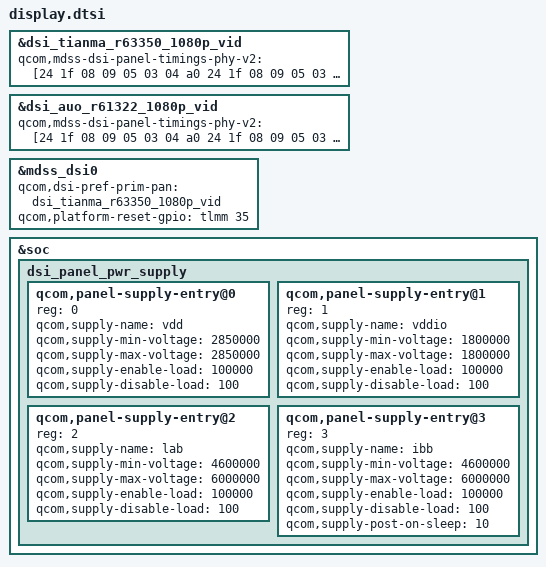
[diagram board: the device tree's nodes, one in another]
/* msm8953-mdss-panels.dtsi */
#include "panel/dsi-panel-tianma-r63350-1080p-video.dtsi"
#include "panel/dsi-panel-auo-r61322-1080p-video.dtsi"

&dsi_tianma_r63350_1080p_vid {
	qcom,mdss-dsi-panel-timings-phy-v2 = [24 1f 08 09 05 03 04 a0
		24 1f 08 09 05 03 04 a0
		24 1f 08 09 05 03 04 a0
		24 1f 08 09 05 03 04 a0
		24 1b 08 09 05 03 04 a0];
};

&dsi_auo_r61322_1080p_vid {
	qcom,mdss-dsi-panel-timings-phy-v2 = [24 1f 08 09 05 03 04 a0
		24 1f 08 09 05 03 04 a0
		24 1f 08 09 05 03 04 a0
		24 1f 08 09 05 03 04 a0
		24 1b 08 09 05 03 04 a0];
};

/* msm8953-mdss.dtsi */
&mdss_dsi0 {
	/delete-property/ vdd-supply;
};

/* msm8953-mtp.dtsi */
&mdss_dsi0 {
	qcom,dsi-pref-prim-pan = <&dsi_tianma_r63350_1080p_vid>;
	qcom,platform-reset-gpio = <&tlmm 35 0>;
};

/* msm8953-oxygen.dtsi */
&mdss_dsi0 {
	/delete-property/ qcom,platform-bklight-en-gpio;
};

&soc {
	dsi_panel_pwr_supply: dsi_panel_pwr_supply {
		#address-cells = <1>;
		#size-cells = <0>;

		qcom,panel-supply-entry@0 {
			reg = <0>;
			qcom,supply-name = "vdd";
			qcom,supply-min-voltage = <2850000>;
			qcom,supply-max-voltage = <2850000>;
			qcom,supply-enable-load = <100000>;
			qcom,supply-disable-load = <100>;
		};

		qcom,panel-supply-entry@1 {
			reg = <1>;
			qcom,supply-name = "vddio";
			qcom,supply-min-voltage = <1800000>;
			qcom,supply-max-voltage = <1800000>;
			qcom,supply-enable-load = <100000>;
			qcom,supply-disable-load = <100>;
		};
		qcom,panel-supply-entry@2 {
			reg = <2>;
			qcom,supply-name = "lab";
			qcom,supply-min-voltage = <4600000>;
			qcom,supply-max-voltage = <6000000>;
			qcom,supply-enable-load = <100000>;
			qcom,supply-disable-load = <100>;
		};
		qcom,panel-supply-entry@3 {
			reg = <3>;
			qcom,supply-name = "ibb";
			qcom,supply-min-voltage = <4600000>;
			qcom,supply-max-voltage = <6000000>;
			qcom,supply-enable-load = <100000>;
			qcom,supply-disable-load = <100>;
			qcom,supply-post-on-sleep = <10>;
		};
	};
};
